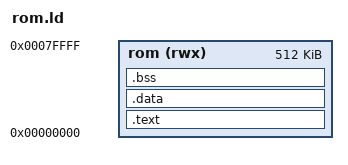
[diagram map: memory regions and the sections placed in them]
OUTPUT_ARCH(m68k)

SEARCH_DIR(.)

MEMORY
{
  rom (rwx) : ORIGIN = 0x0, LENGTH = 0x80000
}

/*
 * stick everything in ROM and mirror it to RAM
 */
SECTIONS
{
  .text :
  {
    CREATE_OBJECT_SYMBOLS
    *(.text .text.*)

    . = ALIGN(0x4);
    /* These are for running static constructors and destructors under ELF.  */
    KEEP (*crtbegin.o(.ctors))
    KEEP (*(EXCLUDE_FILE (*crtend.o) .ctors))
    KEEP (*(SORT(.ctors.*)))
    KEEP (*(.ctors))
    KEEP (*crtbegin.o(.dtors))
    KEEP (*(EXCLUDE_FILE (*crtend.o) .dtors))
    KEEP (*(SORT(.dtors.*)))
    KEEP (*(.dtors))

    *(.rodata .rodata.*)

    . = ALIGN(0x4);
    *(.gcc_except_table)

    . = ALIGN(0x4);
    *(.eh_frame)

    . = ALIGN(0x4);
    _etext = .;
    *(.lit)
  } > rom

  .data :
  {
    _data = .;
    *(.got.plt) *(.got)
    *(.shdata)
    *(.data .data.*)
    . = ALIGN(0x4);
    _edata = .;
  } > rom

  .bss :
  {
    . = ALIGN(0x4);
    __bss_start = . ;
    *(.shbss)
    *(.bss .bss.*)
    *(COMMON)
    _end =  ALIGN (0x8);
    __end = _end;
  } > rom

  .stab 0 (NOLOAD) :
  {
    *(.stab)
  }

  .stabstr 0 (NOLOAD) :
  {
    *(.stabstr)
  }
}
